# MM32F031q register map
File version: 1.01
CPU: CM0 r0p0, little endian, no MPU, no FPU, 2 interrupt priority bits
Registers are 32-bit, read-write, reset 0x0 unless marked. A register's access mark holds for its fields unless they carry their own. Offsets are from the block's base; [hi:lo] are bit positions; {n}, {i} and the like mark numbered series; 'fields as' and 'values as' point back to an identical list.

## COMP — comparator
Base 0x40013C00
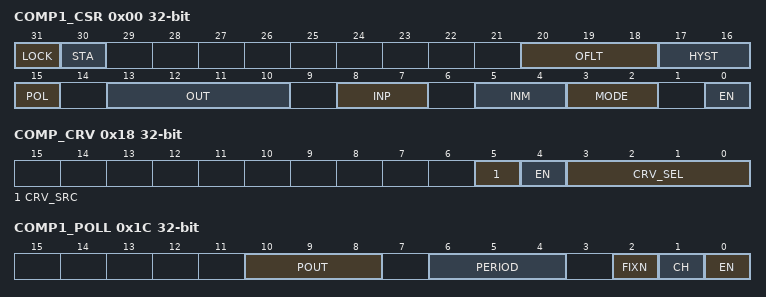
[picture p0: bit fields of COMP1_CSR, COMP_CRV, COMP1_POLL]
0x00 COMP1_CSR
  [31] LOCK — Comparator 1 lock
  [30] STA — Comparator 1 output status
  [20:18] OFLT — Comparator 1 output filter
  [17:16] HYST — Comparator 1 hysteresis
  [15] POL — Comparator 1 output polarity
  [13:10] OUT — Comparator 1 output selection
  [8:7] INP — Comparator 1 normal phase input selection
  [5:4] INM — Comparator 1 inverting input selection
  [3:2] MODE — Comparator 1 mode
  [0] EN — Comparator 1 enable
0x18 COMP_CRV
  [5] CRV_SRC — Comparator external refer-ence voltage source select
  [4] EN — Comparator external referencevoltage enable
  [3:0] CRV_SEL — Comparator external referencevoltage select
0x1C COMP1_POLL
  [10:8] POUT — Comparator 1 Polling output
  [6:4] PERIOD — Comparator 1 polling wait cycle
  [2] FIXN — Comparator 1 Polling inverting input fix
  [1] CH — Comparator 1 polling channel
  [0] EN — Comparator 1 polling enable

## CRC — CRC calculation unit
Base 0x40023000
0x00 DR reset 0xFFFFFFFF — Data register
  [31:0] DR — Data register bits
0x04 IDR — Independent data register
  [7:0] IDR — General-purpose 8-bit data register bits
0x08 CR wo — Control register
  [0] RESET — CRC reset

## DBG — Debug support
Base 0x40013400
0x00 IDCODE ro
  [31:0] DEV_ID — Device identifier
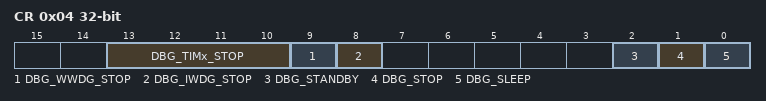
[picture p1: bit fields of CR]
0x04 CR wo
  [13:10] DBG_TIMx_STOP — TIMx counter stopped when core is halted
  [9] DBG_WWDG_STOP — Debug window watchdog when core is halted
  [8] DBG_IWDG_STOP — Debug independent watchdog stopped when core is stopped
  [2] DBG_STANDBY — Debug Standby mode
  [1] DBG_STOP — Debug Stop mode
  [0] DBG_SLEEP — Debug Sleep mode

## DEVICE
Base 0x1FFFF7E8
0x00 UID1 16-bit read — Configuration register
  [15:0] U_ID — 15:0 unique ID bits
0x02 UID2 16-bit read — Configuration register
  [15:0] U_ID — 31:16 unique ID bits
0x04 UID3 read — Configuration register
  [31:0] U_ID — 63:32 unique ID bits
0x08 UID4 read — Configuration register
  [31:0] U_ID — 95:64 unique ID bits

## DIV — Hardware divider
Base 0x40030000
0x00 DVDR
  [31:0] DIVIDEND — Dividend data
0x04 DVSR reset 0x1
  [31:0] DIVISOR — Divisor data
0x08 QUOTR read
  [31:0] QUOTIENT — Quotient data
0x0C RMDR read
  [31:0] REMAINDER — Remainder data
0x10 SR read
  [0] OVF — Overflow flag
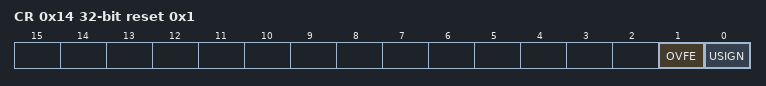
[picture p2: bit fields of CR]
0x14 CR reset 0x1
  [1] OVFE — Overflow interrupt enable
  [0] USIGN — unsigned enable

## DMA1 — DMA1 controller
Base 0x40020000
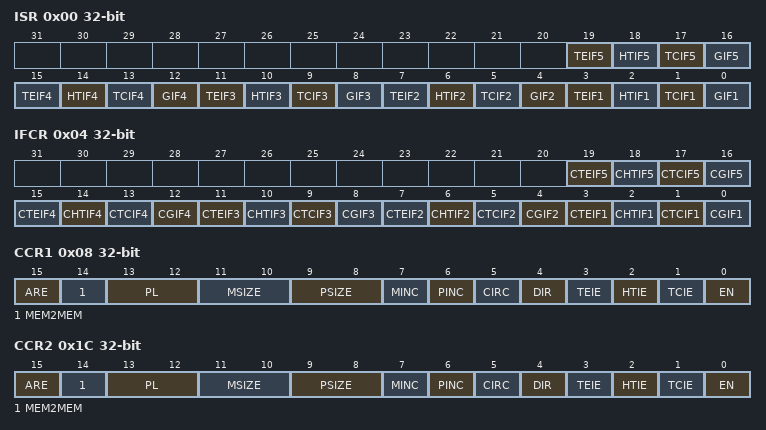
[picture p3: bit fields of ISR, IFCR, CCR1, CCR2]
0x00 ISR ro
  [4n-1] TEIF{n} (n=1..5) — channel {n} transfer error flag
  [4n-2] HTIF{n} (n=1..5) — channel {n} half transfer flag
  [4n-3] TCIF{n} (n=1..5) — channel {n} transfer complete flag
  [4n-4] GIF{n} (n=1..5) — channel {n} global interrupt flag
0x04 IFCR
  [4n-1] CTEIF{n} (n=1..5) — channel {n} transfer error clear
  [4n-2] CHTIF{n} (n=1..5) — channel {n} half transfer clear
  [4n-3] CTCIF{n} (n=1..5) — channel {n} transfer complete clear
  [4n-4] CGIF{n} (n=1..5) — channel {n} global interrupt clear
0x08 CCR1
  [15] ARE — Auto-Reload Enable bit
  [14] MEM2MEM — Memory to memory mode
  [13:12] PL — Channel priority level
  [11:10] MSIZE — Memory size
  [9:8] PSIZE — Peripheral size
  [7] MINC — Memory increment mode
  [6] PINC — Peripheral increment mode
  [5] CIRC — Circular mode
  [4] DIR — Data transfer direction
  [3] TEIE — Transfer error interrupt enable
  [2] HTIE — Half transfer interrupt enable
  [1] TCIE — Transfer complete interrupt enable
  [0] EN — Channel enable
0x0C CNDTR1
  [15:0] NDT — Number of data to transfer
0x10 CPAR1
  [31:0] PA — Peripheral address
{0x0+0x14*i} CMAR{i} (i=1..5)
  [31:0] MA — Memory address
0x1C CCR2
  fields as CCR1
0x20 CNDTR2
  [15:0] NDT — Number of data to transfer
0x24 CPAR2
  [31:0] PA — Peripheral address
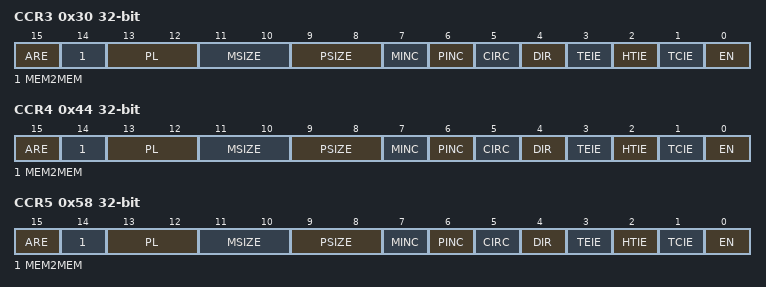
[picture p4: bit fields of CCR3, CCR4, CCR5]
0x30 CCR3
  fields as CCR1
0x34 CNDTR3
  [15:0] NDT — Number of data to transfer
0x38 CPAR3
  [31:0] PA — Peripheral address
0x44 CCR4
  fields as CCR1
0x48 CNDTR4
  [15:0] NDT — Number of data to transfer
0x4C CPAR4
  [31:0] PA — Peripheral address
0x58 CCR5
  fields as CCR1
0x5C CNDTR5
  [15:0] NDT — Number of data to transfer
0x60 CPAR5
  [31:0] PA — Peripheral address
